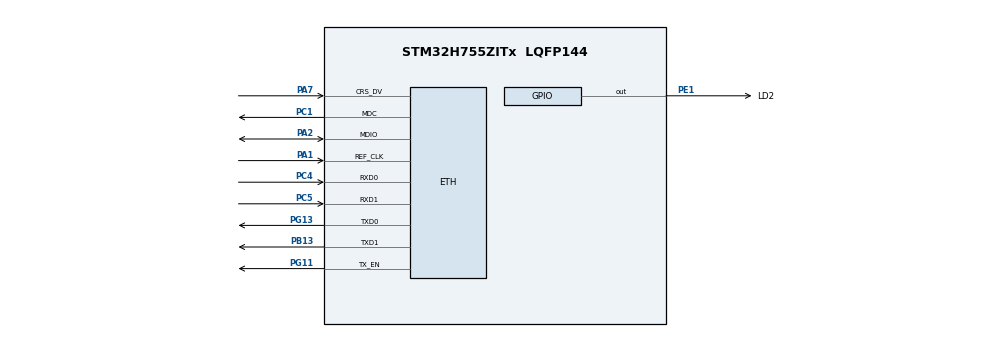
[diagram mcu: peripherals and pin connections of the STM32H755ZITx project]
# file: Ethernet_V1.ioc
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CORTEX_M7.AccessPermission-Cortex_Memory_Protection_Unit_Region1_Settings=MPU_REGION_FULL_ACCESS
CORTEX_M7.AccessPermission-Cortex_Memory_Protection_Unit_Region2_Settings=MPU_REGION_FULL_ACCESS
CORTEX_M7.BaseAddress-Cortex_Memory_Protection_Unit_Region1_Settings=0x30002000
CORTEX_M7.BaseAddress-Cortex_Memory_Protection_Unit_Region2_Settings=0x30000000
CORTEX_M7.CPU_DCache=Enabled
CORTEX_M7.CPU_ICache=Enabled
CORTEX_M7.DisableExec-Cortex_Memory_Protection_Unit_Region0_Settings=MPU_INSTRUCTION_ACCESS_DISABLE
CORTEX_M7.DisableExec-Cortex_Memory_Protection_Unit_Region1_Settings=MPU_INSTRUCTION_ACCESS_DISABLE
CORTEX_M7.DisableExec-Cortex_Memory_Protection_Unit_Region2_Settings=MPU_INSTRUCTION_ACCESS_DISABLE
CORTEX_M7.Enable-Cortex_Memory_Protection_Unit_Region0_Settings=MPU_REGION_ENABLE
CORTEX_M7.Enable-Cortex_Memory_Protection_Unit_Region1_Settings=MPU_REGION_ENABLE
CORTEX_M7.Enable-Cortex_Memory_Protection_Unit_Region2_Settings=MPU_REGION_ENABLE
CORTEX_M7.IsBufferable-Cortex_Memory_Protection_Unit_Region2_Settings=MPU_ACCESS_BUFFERABLE
CORTEX_M7.IsShareable-Cortex_Memory_Protection_Unit_Region0_Settings=MPU_ACCESS_SHAREABLE
CORTEX_M7.IsShareable-Cortex_Memory_Protection_Unit_Region2_Settings=MPU_ACCESS_SHAREABLE
CORTEX_M7.MPU_Control=MPU_PRIVILEGED_DEFAULT
CORTEX_M7.Size-Cortex_Memory_Protection_Unit_Region0_Settings=MPU_REGION_SIZE_4GB
CORTEX_M7.Size-Cortex_Memory_Protection_Unit_Region1_Settings=MPU_REGION_SIZE_128KB
CORTEX_M7.Size-Cortex_Memory_Protection_Unit_Region2_Settings=MPU_REGION_SIZE_256B
CORTEX_M7.SubRegionDisable-Cortex_Memory_Protection_Unit_Region0_Settings=0x87
CORTEX_M7.TypeExtField-Cortex_Memory_Protection_Unit_Region1_Settings=MPU_TEX_LEVEL1
CortexM4.IPs=FATFS_M4\:I,FREERTOS_M4\:I,IWDG2\:I,RCC,WWDG2\:I,DMA,BDMA,MDMA,NVIC2\:I,USART3,DEBUG,PDM2PCM_M4\:I,PWR,RESMGR_UTILITY,SYS_M4\:I,USB_DEVICE_M4\:I,USB_HOST_M4\:I,CORTEX_M4\:I,GPIO,OPENAMP_M4\:I,VREFBUF
CortexM7.IPs=FATFS_M7\:I,FREERTOS_M7\:I,IWDG1\:I,RCC\:I,WWDG1\:I,DMA\:I,BDMA\:I,MDMA\:I,NVIC1\:I,ETH\:I,USART3\:I,USB_OTG_FS\:I,SYS\:I,CORTEX_M7\:I,DEBUG\:I,PDM2PCM_M7\:I,PWR\:I,RESMGR_UTILITY\:I,USB_DEVICE_M7\:I,USB_HOST_M7\:I,GPIO\:I,OPENAMP_M7\:I,VREFBUF\:I,NUCLEO-H755ZI-Q\:I,MEMORYMAP\:I,LWIP\:I
ETH.MediaInterface=HAL_ETH_RMII_MODE
ETH.RxBufferAddress=0x30000200
ETH.RxDescAddress=0x30000000
ETH.TxDescAddress=0x30000100
LWIP.BSP.number=1
LWIP.GATEWAY_ADDRESS=192.168.001.001
LWIP.IP_ADDRESS=192.168.001.120
LWIP.LWIP_DHCP=0
LWIP.LWIP_RAM_HEAP_POINTER=0x30002000
LWIP.NETMASK_ADDRESS=255.255.255.000
LWIP.Version=v2.1.2_Cube
LWIP0.BSP.STBoard=false
LWIP0.BSP.api=BSP_COMPONENT_DRIVER
LWIP0.BSP.component=LAN8742
LWIP0.BSP.instance=LAN8742
LWIP0.BSP.name=Driver_PHY
LWIP0.BSP.semaphore=S_LAN8742
LWIP0.BSP.solution=LAN8742
Mcu.Family=STM32H7
Mcu.Name=STM32H755ZITx
Mcu.Package=LQFP144
NUCLEO-H755ZI-Q.BUTTON=2
NUCLEO-H755ZI-Q.LD1=true
NUCLEO-H755ZI-Q.LD2=true
NUCLEO-H755ZI-Q.LD3=true
NVIC1.PriorityGroup=NVIC_PRIORITYGROUP_4
NVIC2.PriorityGroup=NVIC_PRIORITYGROUP_4
PA1.GPIO_Speed=GPIO_SPEED_FREQ_VERY_HIGH
PA1.Mode=RMII
PA1.PinAttribute=CortexM7
PA1.Signal=ETH_REF_CLK
PA2.GPIO_Speed=GPIO_SPEED_FREQ_VERY_HIGH
PA2.Mode=RMII
PA2.PinAttribute=CortexM7
PA2.Signal=ETH_MDIO
PA7.GPIO_Speed=GPIO_SPEED_FREQ_VERY_HIGH
PA7.Mode=RMII
PA7.PinAttribute=CortexM7
PA7.Signal=ETH_CRS_DV
PB0.TagName=LD1
PB13.GPIO_Speed=GPIO_SPEED_FREQ_VERY_HIGH
PB13.Mode=RMII
PB13.PinAttribute=CortexM7
PB13.Signal=ETH_TXD1
PC1.GPIO_Speed=GPIO_SPEED_FREQ_LOW
PC1.Mode=RMII
PC1.PinAttribute=CortexM7
PC1.Signal=ETH_MDC
PC4.GPIO_Speed=GPIO_SPEED_FREQ_VERY_HIGH
PC4.Mode=RMII
PC4.PinAttribute=CortexM7
PC4.Signal=ETH_RXD0
PC5.GPIO_Speed=GPIO_SPEED_FREQ_VERY_HIGH
PC5.Mode=RMII
PC5.PinAttribute=CortexM7
PC5.Signal=ETH_RXD1
PE1.GPIO_Label=LD2
PE1.PinAttribute=Free
PE1.Signal=GPIO_Output
PE1.TagName=LD2
PG11.GPIO_Speed=GPIO_SPEED_FREQ_VERY_HIGH
PG11.Mode=RMII
PG11.PinAttribute=CortexM7
PG11.Signal=ETH_TX_EN
PG13.GPIO_Speed=GPIO_SPEED_FREQ_VERY_HIGH
PG13.Mode=RMII
PG13.PinAttribute=CortexM7
PG13.Signal=ETH_TXD0
PH0-OSC_IN\ (PH0).Mode=HSE-External-Oscillator
PH0-OSC_IN\ (PH0).PinAttribute=Free
PH0-OSC_IN\ (PH0).Signal=RCC_OSC_IN
PH1-OSC_OUT\ (PH1).Mode=HSE-External-Oscillator
PH1-OSC_OUT\ (PH1).PinAttribute=Free
PH1-OSC_OUT\ (PH1).Signal=RCC_OSC_OUT
ProjectManager.HeapSize=M4-0x200,M7-0x200
ProjectManager.StackSize=M4-0x400,M7-0x400
ProjectManager.TargetToolchain=STM32CubeIDE
RCC.ADCFreq_Value=129000000
RCC.APB1Freq_Value=108000000
RCC.APB2Freq_Value=108000000
RCC.APB3Freq_Value=108000000
RCC.APB4Freq_Value=108000000
RCC.CortexFreq_Value=216000000
RCC.D1PPRE=RCC_APB3_DIV2
RCC.D2PPRE1=RCC_APB1_DIV2
RCC.D2PPRE2=RCC_APB2_DIV2
RCC.D3PPRE=RCC_APB4_DIV2
RCC.DIVM1=4
RCC.DIVN1=27
RCC.DIVQ1=5
RCC.HCLKFreq_Value=216000000
RCC.PLL2FRACN=0
RCC.PLL3FRACN=0
RCC.PLLFRACN=0
RCC.SYSCLKFreq_VALUE=216000000
RCC.SYSCLKSource=RCC_SYSCLKSOURCE_PLLCLK
RCC.SupplySource=PWR_DIRECT_SMPS_SUPPLY
RCC.USBFreq_Value=86400000
VP_LWIP_VS_Enabled.Mode=Enabled
VP_MEMORYMAP_VS_MEMORYMAP.Mode=CurAppReg
VP_NUCLEO-H755ZI-Q_VS_BSP_COMMON.Mode=COMMON
VP_SYS_M4_VS_Systick.Mode=SysTick
board=NUCLEO-H755ZI-Q

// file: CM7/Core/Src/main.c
/* USER CODE BEGIN Header */
/**
  ******************************************************************************
  * @file           : main.c
  * @brief          : Main program body
  ******************************************************************************
  * @attention
  *
  * Copyright (c) 2025 STMicroelectronics.
  * All rights reserved.
  *
  * This software is licensed under terms that can be found in the LICENSE file
  * in the root directory of this software component.
  * If no LICENSE file comes with this software, it is provided AS-IS.
  *
  ******************************************************************************
  */
/* USER CODE END Header */
#include "main.h"
#include "lwip.h"
//#include "lwip/udp.h"
/* USER CODE BEGIN Includes */
//#include <string.h>
/* USER CODE END Includes */

/* USER CODE BEGIN PD */

/* DUAL_CORE_BOOT_SYNC_SEQUENCE: Define for dual core boot synchronization    */
/*                             demonstration code based on hardware semaphore */
/* This define is present in both CM7/CM4 projects                            */
/* To comment when developping/debugging on a single core                     */
#define DUAL_CORE_BOOT_SYNC_SEQUENCE

#if defined(DUAL_CORE_BOOT_SYNC_SEQUENCE)
#ifndef HSEM_ID_0
#define HSEM_ID_0 (0U) /* HW semaphore 0*/
#endif
#endif /* DUAL_CORE_BOOT_SYNC_SEQUENCE */

/* USER CODE END PD */

void SystemClock_Config(void);
static void MPU_Config(void);
static void MX_GPIO_Init(void);

int main(void)
{

/* USER CODE BEGIN Boot_Mode_Sequence_0 */
#if defined(DUAL_CORE_BOOT_SYNC_SEQUENCE)
  int32_t timeout;
#endif /* DUAL_CORE_BOOT_SYNC_SEQUENCE */
/* USER CODE END Boot_Mode_Sequence_0 */

  /* MPU Configuration--------------------------------------------------------*/
  MPU_Config();

  /* Enable the CPU Cache */

  /* Enable I-Cache---------------------------------------------------------*/
  SCB_EnableICache();

  /* Enable D-Cache---------------------------------------------------------*/
  SCB_EnableDCache();

/* USER CODE BEGIN Boot_Mode_Sequence_1 */
#if defined(DUAL_CORE_BOOT_SYNC_SEQUENCE)
  /* Wait until CPU2 boots and enters in stop mode or timeout*/
  timeout = 0xFFFF;
  while((__HAL_RCC_GET_FLAG(RCC_FLAG_D2CKRDY) != RESET) && (timeout-- > 0));
  if ( timeout < 0 )
  {
  Error_Handler();
  }
#endif /* DUAL_CORE_BOOT_SYNC_SEQUENCE */
/* USER CODE END Boot_Mode_Sequence_1 */
  /* MCU Configuration--------------------------------------------------------*/

  /* Reset of all peripherals, Initializes the Flash interface and the Systick. */
  HAL_Init();

  /* Configure the system clock */
  SystemClock_Config();
/* USER CODE BEGIN Boot_Mode_Sequence_2 */
#if defined(DUAL_CORE_BOOT_SYNC_SEQUENCE)
/* When system initialization is finished, Cortex-M7 will release Cortex-M4 by means of
HSEM notification */
/*HW semaphore Clock enable*/
__HAL_RCC_HSEM_CLK_ENABLE();
/*Take HSEM */
HAL_HSEM_FastTake(HSEM_ID_0);
/*Release HSEM in order to notify the CPU2(CM4)*/
HAL_HSEM_Release(HSEM_ID_0,0);
/* wait until CPU2 wakes up from stop mode */
timeout = 0xFFFF;
while((__HAL_RCC_GET_FLAG(RCC_FLAG_D2CKRDY) == RESET) && (timeout-- > 0));
if ( timeout < 0 )
{
Error_Handler();
}
#endif /* DUAL_CORE_BOOT_SYNC_SEQUENCE */
/* USER CODE END Boot_Mode_Sequence_2 */

  /* Initialize all configured peripherals */
  MX_GPIO_Init();
  MX_LWIP_Init();
  /* USER CODE BEGIN 2 */
  uint32_t count = 0;

  /* USER CODE END 2 */

  /* Initialize leds */
  BSP_LED_Init(LED_GREEN);
  BSP_LED_Init(LED_YELLOW);
  BSP_LED_Init(LED_RED);

  /* Initialize User push-button without interrupt mode. */
  BSP_PB_Init(BUTTON_USER, BUTTON_MODE_GPIO);

  /* Infinite loop */
  /* USER CODE BEGIN WHILE */
  while (1)
  {
	  MX_LWIP_Process();
    /* USER CODE END WHILE */

    /* USER CODE BEGIN 3 */
	    /* Flashing LEDs to see nothing hangs */
	    if (count++ & 0x020000)
	    {
	      BSP_LED_On(LED_GREEN);
	    }
	    else
	    {
	      BSP_LED_Off(LED_GREEN);
	    }
  }
  /* USER CODE END 3 */
}

void SystemClock_Config(void)
{
  RCC_OscInitTypeDef RCC_OscInitStruct = {0};
  RCC_ClkInitTypeDef RCC_ClkInitStruct = {0};

  /** Supply configuration update enable
  */
  HAL_PWREx_ConfigSupply(PWR_DIRECT_SMPS_SUPPLY);

  /** Configure the main internal regulator output voltage
  */
  __HAL_PWR_VOLTAGESCALING_CONFIG(PWR_REGULATOR_VOLTAGE_SCALE2);

  while(!__HAL_PWR_GET_FLAG(PWR_FLAG_VOSRDY)) {}

  /** Initializes the RCC Oscillators according to the specified parameters
  * in the RCC_OscInitTypeDef structure.
  */
  RCC_OscInitStruct.OscillatorType = RCC_OSCILLATORTYPE_HSI;
  RCC_OscInitStruct.HSIState = RCC_HSI_DIV1;
  RCC_OscInitStruct.HSICalibrationValue = RCC_HSICALIBRATION_DEFAULT;
  RCC_OscInitStruct.PLL.PLLState = RCC_PLL_ON;
  RCC_OscInitStruct.PLL.PLLSource = RCC_PLLSOURCE_HSI;
  RCC_OscInitStruct.PLL.PLLM = 4;
  RCC_OscInitStruct.PLL.PLLN = 27;
  RCC_OscInitStruct.PLL.PLLP = 2;
  RCC_OscInitStruct.PLL.PLLQ = 5;
  RCC_OscInitStruct.PLL.PLLR = 2;
  RCC_OscInitStruct.PLL.PLLRGE = RCC_PLL1VCIRANGE_3;
  RCC_OscInitStruct.PLL.PLLVCOSEL = RCC_PLL1VCOWIDE;
  RCC_OscInitStruct.PLL.PLLFRACN = 0;
  if (HAL_RCC_OscConfig(&RCC_OscInitStruct) != HAL_OK)
  {
    Error_Handler();
  }

  /** Initializes the CPU, AHB and APB buses clocks
  */
  RCC_ClkInitStruct.ClockType = RCC_CLOCKTYPE_HCLK|RCC_CLOCKTYPE_SYSCLK
                              |RCC_CLOCKTYPE_PCLK1|RCC_CLOCKTYPE_PCLK2
                              |RCC_CLOCKTYPE_D3PCLK1|RCC_CLOCKTYPE_D1PCLK1;
  RCC_ClkInitStruct.SYSCLKSource = RCC_SYSCLKSOURCE_PLLCLK;
  RCC_ClkInitStruct.SYSCLKDivider = RCC_SYSCLK_DIV1;
  RCC_ClkInitStruct.AHBCLKDivider = RCC_HCLK_DIV1;
  RCC_ClkInitStruct.APB3CLKDivider = RCC_APB3_DIV2;
  RCC_ClkInitStruct.APB1CLKDivider = RCC_APB1_DIV2;
  RCC_ClkInitStruct.APB2CLKDivider = RCC_APB2_DIV2;
  RCC_ClkInitStruct.APB4CLKDivider = RCC_APB4_DIV2;

  if (HAL_RCC_ClockConfig(&RCC_ClkInitStruct, FLASH_LATENCY_3) != HAL_OK)
  {
    Error_Handler();
  }
}

static void MX_GPIO_Init(void)
{

  /* GPIO Ports Clock Enable */
  __HAL_RCC_GPIOC_CLK_ENABLE();
  __HAL_RCC_GPIOA_CLK_ENABLE();
  __HAL_RCC_GPIOB_CLK_ENABLE();
  __HAL_RCC_GPIOG_CLK_ENABLE();

}

 /* MPU Configuration */

void MPU_Config(void)
{
  MPU_Region_InitTypeDef MPU_InitStruct = {0};

  /* Disables the MPU */
  HAL_MPU_Disable();

  /** Initializes and configures the Region and the memory to be protected
  */
  MPU_InitStruct.Enable = MPU_REGION_ENABLE;
  MPU_InitStruct.Number = MPU_REGION_NUMBER0;
  MPU_InitStruct.BaseAddress = 0x0;
  MPU_InitStruct.Size = MPU_REGION_SIZE_4GB;
  MPU_InitStruct.SubRegionDisable = 0x87;
  MPU_InitStruct.TypeExtField = MPU_TEX_LEVEL0;
  MPU_InitStruct.AccessPermission = MPU_REGION_NO_ACCESS;
  MPU_InitStruct.DisableExec = MPU_INSTRUCTION_ACCESS_DISABLE;
  MPU_InitStruct.IsShareable = MPU_ACCESS_SHAREABLE;
  MPU_InitStruct.IsCacheable = MPU_ACCESS_NOT_CACHEABLE;
  MPU_InitStruct.IsBufferable = MPU_ACCESS_NOT_BUFFERABLE;

  HAL_MPU_ConfigRegion(&MPU_InitStruct);

  /** Initializes and configures the Region and the memory to be protected
  */
  MPU_InitStruct.Number = MPU_REGION_NUMBER1;
  MPU_InitStruct.BaseAddress = 0x30002000;
  MPU_InitStruct.Size = MPU_REGION_SIZE_128KB;
  MPU_InitStruct.SubRegionDisable = 0x0;
  MPU_InitStruct.TypeExtField = MPU_TEX_LEVEL1;
  MPU_InitStruct.AccessPermission = MPU_REGION_FULL_ACCESS;
  MPU_InitStruct.IsShareable = MPU_ACCESS_NOT_SHAREABLE;

  HAL_MPU_ConfigRegion(&MPU_InitStruct);

  /** Initializes and configures the Region and the memory to be protected
  */
  MPU_InitStruct.Number = MPU_REGION_NUMBER2;
  MPU_InitStruct.BaseAddress = 0x30000000;
  MPU_InitStruct.Size = MPU_REGION_SIZE_256B;
  MPU_InitStruct.TypeExtField = MPU_TEX_LEVEL0;
  MPU_InitStruct.IsShareable = MPU_ACCESS_SHAREABLE;
  MPU_InitStruct.IsBufferable = MPU_ACCESS_BUFFERABLE;

  HAL_MPU_ConfigRegion(&MPU_InitStruct);
  /* Enables the MPU */
  HAL_MPU_Enable(MPU_PRIVILEGED_DEFAULT);

}

void Error_Handler(void)
{
  __disable_irq();
  while (1)
  {
  }
}
